AUTOSAR XML (schema 4-3-0)
standard types defined: Boolean, UInt8, SInt8, UInt16, SInt16, UInt32, SInt32, boolean, uint8, sint8, uint16, sint16, uint32, sint32
package /Components
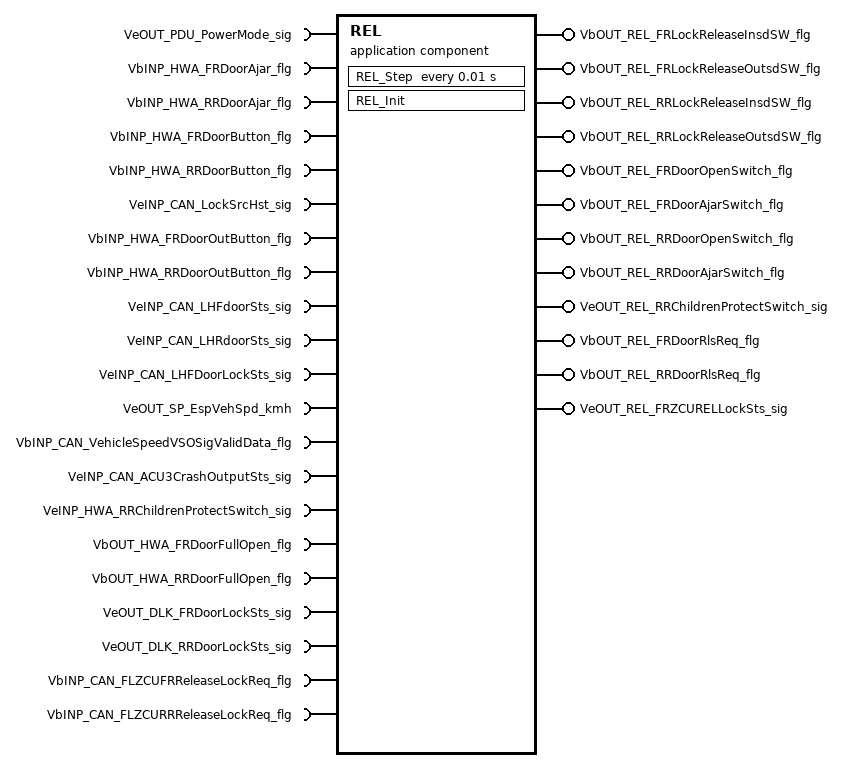
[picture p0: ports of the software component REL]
  application sw component type REL
    21 x require port:
      VeOUT_PDU_PowerMode_sig: nonqueued-receiver-com-spec{data-element=VeOUT_PDU_PowerMode_sig, init-value=0}, required-interface=VeOUT_PDU_PowerMode_sig
      VbINP_HWA_FRDoorAjar_flg: nonqueued-receiver-com-spec{data-element=VbINP_HWA_FRDoorAjar_flg, init-value=0}, required-interface=VbINP_HWA_FRDoorAjar_flg
      VbINP_HWA_RRDoorAjar_flg: nonqueued-receiver-com-spec{data-element=VbINP_HWA_RRDoorAjar_flg, init-value=0}, required-interface=VbINP_HWA_RRDoorAjar_flg
      VbINP_HWA_FRDoorButton_flg: nonqueued-receiver-com-spec{data-element=VbINP_HWA_FRDoorButton_flg, init-value=0}, required-interface=VbINP_HWA_FRDoorButton_flg
      VbINP_HWA_RRDoorButton_flg: nonqueued-receiver-com-spec{data-element=VbINP_HWA_RRDoorButton_flg, init-value=0}, required-interface=VbINP_HWA_RRDoorButton_flg
      VeINP_CAN_LockSrcHst_sig: nonqueued-receiver-com-spec{data-element=VeINP_CAN_LockSrcHst_sig, init-value=0}, required-interface=VeINP_CAN_LockSrcHst_sig
      VbINP_HWA_FRDoorOutButton_flg: nonqueued-receiver-com-spec{data-element=VbINP_HWA_FRDoorOutButton_flg, init-value=0}, required-interface=VbINP_HWA_FRDoorOutButton_flg
      VbINP_HWA_RRDoorOutButton_flg: nonqueued-receiver-com-spec{data-element=VbINP_HWA_RRDoorOutButton_flg, init-value=0}, required-interface=VbINP_HWA_RRDoorOutButton_flg
      VeINP_CAN_LHFdoorSts_sig: nonqueued-receiver-com-spec{data-element=VeINP_CAN_LHFdoorSts_sig, init-value=0}, required-interface=VeINP_CAN_LHFdoorSts_sig
      VeINP_CAN_LHRdoorSts_sig: nonqueued-receiver-com-spec{data-element=VeINP_CAN_LHRdoorSts_sig, init-value=0}, required-interface=VeINP_CAN_LHRdoorSts_sig
      VeINP_CAN_LHFDoorLockSts_sig: nonqueued-receiver-com-spec{data-element=VeINP_CAN_LHFDoorLockSts_sig, init-value=0}, required-interface=VeINP_CAN_LHFDoorLockSts_sig
      VeOUT_SP_EspVehSpd_kmh: nonqueued-receiver-com-spec{data-element=VeOUT_SP_EspVehSpd_kmh, init-value=0}, required-interface=VeOUT_SP_EspVehSpd_kmh
      VbINP_CAN_VehicleSpeedVSOSigValidData_flg: nonqueued-receiver-com-spec{data-element=VbINP_CAN_VehicleSpeedVSOSigValidData_flg, init-value=0}, required-interface=VbINP_CAN_VehicleSpeedVSOSigValidData_flg
      VeINP_CAN_ACU3CrashOutputSts_sig: nonqueued-receiver-com-spec{data-element=VeINP_CAN_ACU3CrashOutputSts_sig, init-value=0}, required-interface=VeINP_CAN_ACU3CrashOutputSts_sig
      VeINP_HWA_RRChildrenProtectSwitch_sig: nonqueued-receiver-com-spec{data-element=VeINP_HWA_RRChildrenProtectSwitch_sig, init-value=0}, required-interface=VeINP_HWA_RRChildrenProtectSwitch_sig
      VbOUT_HWA_FRDoorFullOpen_flg: nonqueued-receiver-com-spec{data-element=VbOUT_HWA_FRDoorFullOpen_flg, init-value=0}, required-interface=VbOUT_HWA_FRDoorFullOpen_flg
      VbOUT_HWA_RRDoorFullOpen_flg: nonqueued-receiver-com-spec{data-element=VbOUT_HWA_RRDoorFullOpen_flg, init-value=0}, required-interface=VbOUT_HWA_RRDoorFullOpen_flg
      VeOUT_DLK_FRDoorLockSts_sig: nonqueued-receiver-com-spec{data-element=VeOUT_DLK_FRDoorLockSts_sig, init-value=0}, required-interface=VeOUT_DLK_FRDoorLockSts_sig
      VeOUT_DLK_RRDoorLockSts_sig: nonqueued-receiver-com-spec{data-element=VeOUT_DLK_RRDoorLockSts_sig, init-value=0}, required-interface=VeOUT_DLK_RRDoorLockSts_sig
      VbINP_CAN_FLZCUFRReleaseLockReq_flg: nonqueued-receiver-com-spec{data-element=VbINP_CAN_FLZCUFRReleaseLockReq_flg, init-value=0}, required-interface=VbINP_CAN_FLZCUFRReleaseLockReq_flg
      VbINP_CAN_FLZCURRReleaseLockReq_flg: nonqueued-receiver-com-spec{data-element=VbINP_CAN_FLZCURRReleaseLockReq_flg, init-value=0}, required-interface=VbINP_CAN_FLZCURRReleaseLockReq_flg
    12 x provide port:
      VbOUT_REL_FRLockReleaseInsdSW_flg: nonqueued-sender-com-spec{data-element=VbOUT_REL_FRLockReleaseInsdSW_flg, init-value=0}, provided-interface=VbOUT_REL_FRLockReleaseInsdSW_flg
      VbOUT_REL_FRLockReleaseOutsdSW_flg: nonqueued-sender-com-spec{data-element=VbOUT_REL_FRLockReleaseOutsdSW_flg, init-value=0}, provided-interface=VbOUT_REL_FRLockReleaseOutsdSW_flg
      VbOUT_REL_RRLockReleaseInsdSW_flg: nonqueued-sender-com-spec{data-element=VbOUT_REL_RRLockReleaseInsdSW_flg, init-value=0}, provided-interface=VbOUT_REL_RRLockReleaseInsdSW_flg
      VbOUT_REL_RRLockReleaseOutsdSW_flg: nonqueued-sender-com-spec{data-element=VbOUT_REL_RRLockReleaseOutsdSW_flg, init-value=0}, provided-interface=VbOUT_REL_RRLockReleaseOutsdSW_flg
      VbOUT_REL_FRDoorOpenSwitch_flg: nonqueued-sender-com-spec{data-element=VbOUT_REL_FRDoorOpenSwitch_flg, init-value=0}, provided-interface=VbOUT_REL_FRDoorOpenSwitch_flg
      VbOUT_REL_FRDoorAjarSwitch_flg: nonqueued-sender-com-spec{data-element=VbOUT_REL_FRDoorAjarSwitch_flg, init-value=0}, provided-interface=VbOUT_REL_FRDoorAjarSwitch_flg
      VbOUT_REL_RRDoorOpenSwitch_flg: nonqueued-sender-com-spec{data-element=VbOUT_REL_RRDoorOpenSwitch_flg, init-value=0}, provided-interface=VbOUT_REL_RRDoorOpenSwitch_flg
      VbOUT_REL_RRDoorAjarSwitch_flg: nonqueued-sender-com-spec{data-element=VbOUT_REL_RRDoorAjarSwitch_flg, init-value=0}, provided-interface=VbOUT_REL_RRDoorAjarSwitch_flg
      VeOUT_REL_RRChildrenProtectSwitch_sig: nonqueued-sender-com-spec{data-element=VeOUT_REL_RRChildrenProtectSwitch_sig, init-value=0}, provided-interface=VeOUT_REL_RRChildrenProtectSwitch_sig
      VbOUT_REL_FRDoorRlsReq_flg: nonqueued-sender-com-spec{data-element=VbOUT_REL_FRDoorRlsReq_flg, init-value=0}, provided-interface=VbOUT_REL_FRDoorRlsReq_flg
      VbOUT_REL_RRDoorRlsReq_flg: nonqueued-sender-com-spec{data-element=VbOUT_REL_RRDoorRlsReq_flg, init-value=0}, provided-interface=VbOUT_REL_RRDoorRlsReq_flg
      VeOUT_REL_FRZCURELLockSts_sig: nonqueued-sender-com-spec{data-element=VeOUT_REL_FRZCURELLockSts_sig, init-value=0}, provided-interface=VeOUT_REL_FRZCURELLockSts_sig
    behavior REL: data-type-mapping=DataTypeMappingsSet, handle-termination-and-restart=NO-SUPPORT
      init event REL_InitEvent: start-on-event=REL_Init
      timing event Event_Runnable_Step: start-on-event=REL_Step, period=0.01
      runnable REL_Init
      runnable REL_Step
        data-receive-point-by-arguments:
          21 x access:
            IN_VeOUT_PDU_PowerMode_sig_VeOUT_PDU_PowerMode_sig: accessed-variable=VeOUT_PDU_PowerMode_sig.VeOUT_PDU_PowerMode_sig
            IN_VbINP_HWA_FRDoorAjar_flg_VbINP_HWA_FRDoorAjar_flg: accessed-variable=VbINP_HWA_FRDoorAjar_flg.VbINP_HWA_FRDoorAjar_flg
            IN_VbINP_HWA_RRDoorAjar_flg_VbINP_HWA_RRDoorAjar_flg: accessed-variable=VbINP_HWA_RRDoorAjar_flg.VbINP_HWA_RRDoorAjar_flg
            IN_VbINP_HWA_FRDoorButton_flg_VbINP_HWA_FRDoorButton_flg: accessed-variable=VbINP_HWA_FRDoorButton_flg.VbINP_HWA_FRDoorButton_flg
            IN_VbINP_HWA_RRDoorButton_flg_VbINP_HWA_RRDoorButton_flg: accessed-variable=VbINP_HWA_RRDoorButton_flg.VbINP_HWA_RRDoorButton_flg
            IN_VeINP_CAN_LockSrcHst_sig_VeINP_CAN_LockSrcHst_sig: accessed-variable=VeINP_CAN_LockSrcHst_sig.VeINP_CAN_LockSrcHst_sig
            IN_VbINP_HWA_FRDoorOutButton_flg_VbINP_HWA_FRDoorOutButton_flg: accessed-variable=VbINP_HWA_FRDoorOutButton_flg.VbINP_HWA_FRDoorOutButton_flg
            IN_VbINP_HWA_RRDoorOutButton_flg_VbINP_HWA_RRDoorOutButton_flg: accessed-variable=VbINP_HWA_RRDoorOutButton_flg.VbINP_HWA_RRDoorOutButton_flg
            IN_VeINP_CAN_LHFdoorSts_sig_VeINP_CAN_LHFdoorSts_sig: accessed-variable=VeINP_CAN_LHFdoorSts_sig.VeINP_CAN_LHFdoorSts_sig
            IN_VeINP_CAN_LHRdoorSts_sig_VeINP_CAN_LHRdoorSts_sig: accessed-variable=VeINP_CAN_LHRdoorSts_sig.VeINP_CAN_LHRdoorSts_sig
            IN_VeINP_CAN_LHFDoorLockSts_sig_VeINP_CAN_LHFDoorLockSts_sig: accessed-variable=VeINP_CAN_LHFDoorLockSts_sig.VeINP_CAN_LHFDoorLockSts_sig
            IN_VeOUT_SP_EspVehSpd_kmh_VeOUT_SP_EspVehSpd_kmh: accessed-variable=VeOUT_SP_EspVehSpd_kmh.VeOUT_SP_EspVehSpd_kmh
            IN_VbINP_CAN_VehicleSpeedVSOSigValidData_flg_VbINP_CAN_VehicleSpeedVSOSigValidData_flg: accessed-variable=VbINP_CAN_VehicleSpeedVSOSigValidData_flg.VbINP_CAN_VehicleSpeedVSOSigValidData_flg
            IN_VeINP_CAN_ACU3CrashOutputSts_sig_VeINP_CAN_ACU3CrashOutputSts_sig: accessed-variable=VeINP_CAN_ACU3CrashOutputSts_sig.VeINP_CAN_ACU3CrashOutputSts_sig
            IN_VeINP_HWA_RRChildrenProtectSwitch_sig_VeINP_HWA_RRChildrenProtectSwitch_sig: accessed-variable=VeINP_HWA_RRChildrenProtectSwitch_sig.VeINP_HWA_RRChildrenProtectSwitch_sig
            IN_VbOUT_HWA_FRDoorFullOpen_flg_VbOUT_HWA_FRDoorFullOpen_flg: accessed-variable=VbOUT_HWA_FRDoorFullOpen_flg.VbOUT_HWA_FRDoorFullOpen_flg
            IN_VbOUT_HWA_RRDoorFullOpen_flg_VbOUT_HWA_RRDoorFullOpen_flg: accessed-variable=VbOUT_HWA_RRDoorFullOpen_flg.VbOUT_HWA_RRDoorFullOpen_flg
            IN_VeOUT_DLK_FRDoorLockSts_sig_VeOUT_DLK_FRDoorLockSts_sig: accessed-variable=VeOUT_DLK_FRDoorLockSts_sig.VeOUT_DLK_FRDoorLockSts_sig
            IN_VeOUT_DLK_RRDoorLockSts_sig_VeOUT_DLK_RRDoorLockSts_sig: accessed-variable=VeOUT_DLK_RRDoorLockSts_sig.VeOUT_DLK_RRDoorLockSts_sig
            IN_VbINP_CAN_FLZCUFRReleaseLockReq_flg_VbINP_CAN_FLZCUFRReleaseLockReq_flg: accessed-variable=VbINP_CAN_FLZCUFRReleaseLockReq_flg.VbINP_CAN_FLZCUFRReleaseLockReq_flg
            IN_VbINP_CAN_FLZCURRReleaseLockReq_flg_VbINP_CAN_FLZCURRReleaseLockReq_flg: accessed-variable=VbINP_CAN_FLZCURRReleaseLockReq_flg.VbINP_CAN_FLZCURRReleaseLockReq_flg
        data-send-points:
          12 x access:
            OUT_VbOUT_REL_FRLockReleaseInsdSW_flg_VbOUT_REL_FRLockReleaseInsdSW_flg: accessed-variable=VbOUT_REL_FRLockReleaseInsdSW_flg.VbOUT_REL_FRLockReleaseInsdSW_flg
            OUT_VbOUT_REL_FRLockReleaseOutsdSW_flg_VbOUT_REL_FRLockReleaseOutsdSW_flg: accessed-variable=VbOUT_REL_FRLockReleaseOutsdSW_flg.VbOUT_REL_FRLockReleaseOutsdSW_flg
            OUT_VbOUT_REL_RRLockReleaseInsdSW_flg_VbOUT_REL_RRLockReleaseInsdSW_flg: accessed-variable=VbOUT_REL_RRLockReleaseInsdSW_flg.VbOUT_REL_RRLockReleaseInsdSW_flg
            OUT_VbOUT_REL_RRLockReleaseOutsdSW_flg_VbOUT_REL_RRLockReleaseOutsdSW_flg: accessed-variable=VbOUT_REL_RRLockReleaseOutsdSW_flg.VbOUT_REL_RRLockReleaseOutsdSW_flg
            OUT_VbOUT_REL_FRDoorOpenSwitch_flg_VbOUT_REL_FRDoorOpenSwitch_flg: accessed-variable=VbOUT_REL_FRDoorOpenSwitch_flg.VbOUT_REL_FRDoorOpenSwitch_flg
            OUT_VbOUT_REL_FRDoorAjarSwitch_flg_VbOUT_REL_FRDoorAjarSwitch_flg: accessed-variable=VbOUT_REL_FRDoorAjarSwitch_flg.VbOUT_REL_FRDoorAjarSwitch_flg
            OUT_VbOUT_REL_RRDoorOpenSwitch_flg_VbOUT_REL_RRDoorOpenSwitch_flg: accessed-variable=VbOUT_REL_RRDoorOpenSwitch_flg.VbOUT_REL_RRDoorOpenSwitch_flg
            OUT_VbOUT_REL_RRDoorAjarSwitch_flg_VbOUT_REL_RRDoorAjarSwitch_flg: accessed-variable=VbOUT_REL_RRDoorAjarSwitch_flg.VbOUT_REL_RRDoorAjarSwitch_flg
            OUT_VeOUT_REL_RRChildrenProtectSwitch_sig_VeOUT_REL_RRChildrenProtectSwitch_sig: accessed-variable=VeOUT_REL_RRChildrenProtectSwitch_sig.VeOUT_REL_RRChildrenProtectSwitch_sig
            OUT_VbOUT_REL_FRDoorRlsReq_flg_VbOUT_REL_FRDoorRlsReq_flg: accessed-variable=VbOUT_REL_FRDoorRlsReq_flg.VbOUT_REL_FRDoorRlsReq_flg
            OUT_VbOUT_REL_RRDoorRlsReq_flg_VbOUT_REL_RRDoorRlsReq_flg: accessed-variable=VbOUT_REL_RRDoorRlsReq_flg.VbOUT_REL_RRDoorRlsReq_flg
            OUT_VeOUT_REL_FRZCURELLockSts_sig_VeOUT_REL_FRZCURELLockSts_sig: accessed-variable=VeOUT_REL_FRZCURELLockSts_sig.VeOUT_REL_FRZCURELLockSts_sig
package /Interfaces
  33 x sender receiver interface:
    VeOUT_PDU_PowerMode_sig
      data VeOUT_PDU_PowerMode_sig: category=VALUE, sw-calibration-access=READ-ONLY, type=UInt8
    VbINP_HWA_FRDoorAjar_flg
      data VbINP_HWA_FRDoorAjar_flg: category=BOOLEAN, sw-calibration-access=READ-ONLY, type=Boolean
    VbINP_HWA_RRDoorAjar_flg
      data VbINP_HWA_RRDoorAjar_flg: category=BOOLEAN, sw-calibration-access=READ-ONLY, type=Boolean
    VbINP_HWA_FRDoorButton_flg
      data VbINP_HWA_FRDoorButton_flg: category=BOOLEAN, sw-calibration-access=READ-ONLY, type=Boolean
    VbINP_HWA_RRDoorButton_flg
      data VbINP_HWA_RRDoorButton_flg: category=BOOLEAN, sw-calibration-access=READ-ONLY, type=Boolean
    VeINP_CAN_LockSrcHst_sig
      data VeINP_CAN_LockSrcHst_sig: category=VALUE, sw-calibration-access=READ-ONLY, type=UInt8
    VbINP_HWA_FRDoorOutButton_flg
      data VbINP_HWA_FRDoorOutButton_flg: category=BOOLEAN, sw-calibration-access=READ-ONLY, type=Boolean
    VbINP_HWA_RRDoorOutButton_flg
      data VbINP_HWA_RRDoorOutButton_flg: category=BOOLEAN, sw-calibration-access=READ-ONLY, type=Boolean
    VeINP_CAN_LHFdoorSts_sig
      data VeINP_CAN_LHFdoorSts_sig: category=VALUE, sw-calibration-access=READ-ONLY, type=UInt8
    VeINP_CAN_LHRdoorSts_sig
      data VeINP_CAN_LHRdoorSts_sig: category=VALUE, sw-calibration-access=READ-ONLY, type=UInt8
    VeINP_CAN_LHFDoorLockSts_sig
      data VeINP_CAN_LHFDoorLockSts_sig: category=VALUE, sw-calibration-access=READ-ONLY, type=UInt8
    VeOUT_SP_EspVehSpd_kmh
      data VeOUT_SP_EspVehSpd_kmh: category=VALUE, sw-calibration-access=READ-ONLY, type=UInt8
    VbINP_CAN_VehicleSpeedVSOSigValidData_flg
      data VbINP_CAN_VehicleSpeedVSOSigValidData_flg: category=BOOLEAN, sw-calibration-access=READ-ONLY, type=Boolean
    VeINP_CAN_ACU3CrashOutputSts_sig
      data VeINP_CAN_ACU3CrashOutputSts_sig: category=VALUE, sw-calibration-access=READ-ONLY, type=UInt8
    VeINP_HWA_RRChildrenProtectSwitch_sig
      data VeINP_HWA_RRChildrenProtectSwitch_sig: category=VALUE, sw-calibration-access=READ-ONLY, type=UInt8
    VbOUT_HWA_FRDoorFullOpen_flg
      data VbOUT_HWA_FRDoorFullOpen_flg: category=BOOLEAN, sw-calibration-access=READ-ONLY, type=Boolean
    VbOUT_HWA_RRDoorFullOpen_flg
      data VbOUT_HWA_RRDoorFullOpen_flg: category=BOOLEAN, sw-calibration-access=READ-ONLY, type=Boolean
    VeOUT_DLK_FRDoorLockSts_sig
      data VeOUT_DLK_FRDoorLockSts_sig: category=VALUE, sw-calibration-access=READ-ONLY, type=UInt8
    VeOUT_DLK_RRDoorLockSts_sig
      data VeOUT_DLK_RRDoorLockSts_sig: category=VALUE, sw-calibration-access=READ-ONLY, type=UInt8
    VbINP_CAN_FLZCUFRReleaseLockReq_flg
      data VbINP_CAN_FLZCUFRReleaseLockReq_flg: category=BOOLEAN, sw-calibration-access=READ-ONLY, type=Boolean
    VbINP_CAN_FLZCURRReleaseLockReq_flg
      data VbINP_CAN_FLZCURRReleaseLockReq_flg: category=BOOLEAN, sw-calibration-access=READ-ONLY, type=Boolean
    VbOUT_REL_FRLockReleaseInsdSW_flg
      data VbOUT_REL_FRLockReleaseInsdSW_flg: category=BOOLEAN, sw-calibration-access=READ-ONLY, type=Boolean
    VbOUT_REL_FRLockReleaseOutsdSW_flg
      data VbOUT_REL_FRLockReleaseOutsdSW_flg: category=BOOLEAN, sw-calibration-access=READ-ONLY, type=Boolean
    VbOUT_REL_RRLockReleaseInsdSW_flg
      data VbOUT_REL_RRLockReleaseInsdSW_flg: category=BOOLEAN, sw-calibration-access=READ-ONLY, type=Boolean
    VbOUT_REL_RRLockReleaseOutsdSW_flg
      data VbOUT_REL_RRLockReleaseOutsdSW_flg: category=BOOLEAN, sw-calibration-access=READ-ONLY, type=Boolean
    VbOUT_REL_FRDoorOpenSwitch_flg
      data VbOUT_REL_FRDoorOpenSwitch_flg: category=BOOLEAN, sw-calibration-access=READ-ONLY, type=Boolean
    VbOUT_REL_FRDoorAjarSwitch_flg
      data VbOUT_REL_FRDoorAjarSwitch_flg: category=BOOLEAN, sw-calibration-access=READ-ONLY, type=Boolean
    VbOUT_REL_RRDoorOpenSwitch_flg
      data VbOUT_REL_RRDoorOpenSwitch_flg: category=BOOLEAN, sw-calibration-access=READ-ONLY, type=Boolean
    VbOUT_REL_RRDoorAjarSwitch_flg
      data VbOUT_REL_RRDoorAjarSwitch_flg: category=BOOLEAN, sw-calibration-access=READ-ONLY, type=Boolean
    VeOUT_REL_RRChildrenProtectSwitch_sig
      data VeOUT_REL_RRChildrenProtectSwitch_sig: category=VALUE, sw-calibration-access=READ-ONLY, type=UInt8
    VbOUT_REL_FRDoorRlsReq_flg
      data VbOUT_REL_FRDoorRlsReq_flg: category=BOOLEAN, sw-calibration-access=READ-ONLY, type=Boolean
    VbOUT_REL_RRDoorRlsReq_flg
      data VbOUT_REL_RRDoorRlsReq_flg: category=BOOLEAN, sw-calibration-access=READ-ONLY, type=Boolean
    VeOUT_REL_FRZCURELLockSts_sig
      data VeOUT_REL_FRZCURELLockSts_sig: category=VALUE, sw-calibration-access=READ-ONLY, type=UInt8
package /REL_imp
  swc implementation REL: behavior=REL
    code-descriptors:
      code Default: artifact-descriptors=autosar-engineering-object={short-label=Default, category=SWSRC}
package /DataTypes/SwAddrMethods
  sw addr method CODE: section-type=CODE
  sw addr method CONST: section-type=CONST
  sw addr method VAR: section-type=VAR
package /DataTypes/ApplicationDataTypes
  7 x app type, all with sw-calibration-access=READ-WRITE:
    Boolean: category=BOOLEAN, compu {0=FALSE, 1=TRUE}
    UInt8: category=VALUE, compu {identical}, range phys 0..255
    SInt8: category=VALUE, compu {identical}, range phys -128..127
    UInt16: category=VALUE, compu {identical}, range phys 0..65535
    SInt16: category=VALUE, compu {identical}, range phys -32768..32767
    UInt32: category=VALUE, compu {identical}, range phys 0..4294967295
    SInt32: category=VALUE, compu {identical}, range phys -2147483648..2147483647
  application record data type SEAT_PassOutputs_STRUCT: category=STRUCTURE, sw-calibration-access=READ-WRITE
    4 x application record element:
      LearnSts: category=VALUE, type=UInt8
      CorrectPos_Zero: category=BOOLEAN, type=Boolean
      CorrectPos_Max: category=BOOLEAN, type=Boolean
      ManualCorrectPos: category=VALUE, type=UInt8
  application record data type SPU_EPRMTarPosSts_STRUCT: category=STRUCTURE, sw-calibration-access=READ-WRITE
    5 x application record element, all with category=VALUE, type=SInt16:
      HorizTarPos
      VertiTarPos
      BkAnTarPos
      CushTarPos
      LegTarPos
  application record data type TPMS_WAR_STRUCT: category=STRUCTURE, sw-calibration-access=READ-WRITE
    9 x application record element, all with category=BOOLEAN, type=Boolean:
      SO_WarID_Invalid
      SO_WarID_Duplicated
      SO_WarMissing
      SO_WarLowBat
      SO_WarLeak
      SO_WarHighPressure
      SO_WarLowPressure
      SO_WarHighTemp
      SO_WarSensFault
  application array data type rt_Array_UInt8_20: category=ARRAY, sw-calibration-access=READ-WRITE
    element rt_Array_UInt8_20: category=VALUE, type=UInt8, array-size-semantics=FIXED-SIZE, max-number-of-elements=20
  application array data type rt_Array_UInt8_16: category=ARRAY, sw-calibration-access=READ-WRITE
    element rt_Array_UInt8_16: category=VALUE, type=UInt8, array-size-semantics=FIXED-SIZE, max-number-of-elements=16
package /DataTypes/ApplicationDataTypes/DataConstrs
  range DC_SEAT_PassOutputs_STRUCT: phys 0
  range DC_SPU_EPRMTarPosSts_STRUCT: phys 0
  range DC_TPMS_WAR_STRUCT: phys 0
package /DataTypes/ImplementationDataTypes
  5 x impl type:
    SEAT_PassOutputs_STRUCT: category=STRUCTURE
      4 x element, all with category=TYPE_REFERENCE:
        LearnSts: implementation-data-type=UInt8
        CorrectPos_Zero: implementation-data-type=Boolean
        CorrectPos_Max: implementation-data-type=Boolean
        ManualCorrectPos: implementation-data-type=UInt8
    SPU_EPRMTarPosSts_STRUCT: category=STRUCTURE
      5 x element, all with category=TYPE_REFERENCE, implementation-data-type=SInt16:
        HorizTarPos
        VertiTarPos
        BkAnTarPos
        CushTarPos
        LegTarPos
    TPMS_WAR_STRUCT: category=STRUCTURE
      9 x element, all with category=TYPE_REFERENCE, implementation-data-type=Boolean:
        SO_WarID_Invalid
        SO_WarID_Duplicated
        SO_WarMissing
        SO_WarLowBat
        SO_WarLeak
        SO_WarHighPressure
        SO_WarLowPressure
        SO_WarHighTemp
        SO_WarSensFault
    rt_Array_UInt8_20: category=ARRAY
      element rt_Array_UInt8_20: array-size=20, array-size-semantics=FIXED-SIZE, implementation-data-type=UInt8
    rt_Array_UInt8_16: category=ARRAY
      element rt_Array_UInt8_16: array-size=16, array-size-semantics=FIXED-SIZE, implementation-data-type=UInt8
package /DataTypes/Units
  unit NoUnit: factor-si-to-unit=1, offset-si-to-unit=0
package /DataTypes/DataTypeMappings
  data type mapping set DataTypeMappingsSet
    data-type-maps:
      application-data-type=Boolean, implementation-data-type=Boolean
      application-data-type=UInt8, implementation-data-type=UInt8
      application-data-type=SInt8, implementation-data-type=SInt8
      application-data-type=UInt16, implementation-data-type=UInt16
      application-data-type=SInt16, implementation-data-type=SInt16
      application-data-type=UInt32, implementation-data-type=UInt32
      application-data-type=SInt32, implementation-data-type=SInt32
      application-data-type=SEAT_PassOutputs_STRUCT, implementation-data-type=SEAT_PassOutputs_STRUCT
      application-data-type=SPU_EPRMTarPosSts_STRUCT, implementation-data-type=SPU_EPRMTarPosSts_STRUCT
      application-data-type=TPMS_WAR_STRUCT, implementation-data-type=TPMS_WAR_STRUCT
      application-data-type=rt_Array_UInt8_20, implementation-data-type=rt_Array_UInt8_20
      application-data-type=rt_Array_UInt8_16, implementation-data-type=rt_Array_UInt8_16
